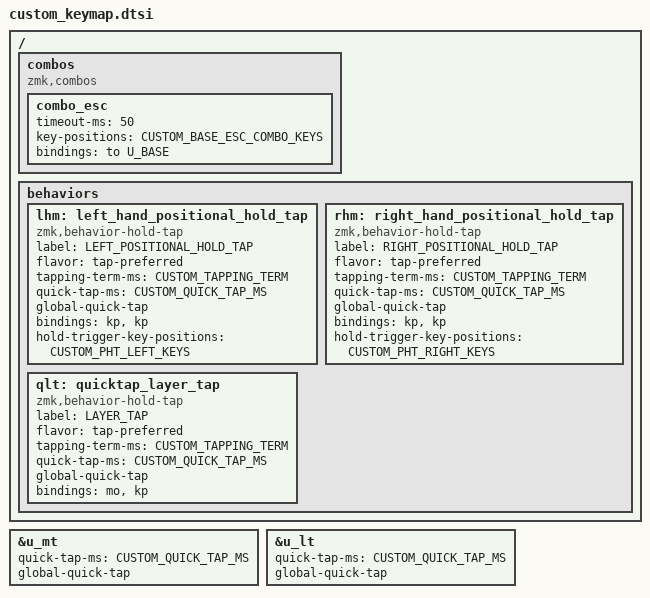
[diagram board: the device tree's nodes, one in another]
#include <behaviors.dtsi>

// 150 is too fast for slower fingers
#define CUSTOM_TAPPING_TERM 170
#define CUSTOM_QUICK_TAP_MS 100

/ {
    combos {
        compatible = "zmk,combos";
        combo_esc {
            timeout-ms = <50>;
            key-positions = <CUSTOM_BASE_ESC_COMBO_KEYS>;
            bindings = <&to U_BASE>;
        };
    };
};
/ {
    behaviors {
        /omit-if-no-ref/ lhm: left_hand_positional_hold_tap {
            compatible = "zmk,behavior-hold-tap";
            label = "LEFT_POSITIONAL_HOLD_TAP";
            #binding-cells = <2>;
            flavor = "tap-preferred";
            tapping-term-ms = <CUSTOM_TAPPING_TERM>;
            quick-tap-ms = <CUSTOM_QUICK_TAP_MS>;
            global-quick-tap;
            bindings = <&kp>, <&kp>;
            hold-trigger-key-positions = <CUSTOM_PHT_LEFT_KEYS>;    // <---[[right-hand keys + left hand thumb]]
        };
        /omit-if-no-ref/ rhm: right_hand_positional_hold_tap {
            compatible = "zmk,behavior-hold-tap";
            label = "RIGHT_POSITIONAL_HOLD_TAP";
            #binding-cells = <2>;
            flavor = "tap-preferred";
            tapping-term-ms = <CUSTOM_TAPPING_TERM>;
            quick-tap-ms = <CUSTOM_QUICK_TAP_MS>;
            global-quick-tap;
            bindings = <&kp>, <&kp>;
            hold-trigger-key-positions = <CUSTOM_PHT_RIGHT_KEYS>;    // <---[[left-hand keys + right hand thumb]]
        };
        /omit-if-no-ref/ qlt: quicktap_layer_tap {
            compatible = "zmk,behavior-hold-tap";
            label = "LAYER_TAP";
            #binding-cells = <2>;
            flavor = "tap-preferred";
            tapping-term-ms = <CUSTOM_TAPPING_TERM>;
            quick-tap-ms = <CUSTOM_QUICK_TAP_MS>;
            global-quick-tap;
            bindings = <&mo>, <&kp>;
        };
    };
};

// override miryoku hm with quick tap
&u_mt {
    quick-tap-ms = <CUSTOM_QUICK_TAP_MS>;
    global-quick-tap;
};
&u_lt {
    quick-tap-ms = <CUSTOM_QUICK_TAP_MS>;
    global-quick-tap;
};

/*
#if defined (MIRYOKU_KLUDGE_MOUSEKEYSPR)
#include <dt-bindings/zmk/mouse.h>
&mwh {
  acceleration-exponent = <1>;
  time-to-max-speed-ms = <2000>;
  delay-ms = <0>;
};
#endif
*/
